# FM33LC0XX register map
File version: 1.0
CPU: Cortex-M0 r1p0, little endian, no MPU, no FPU, 3 interrupt priority bits
Registers are 32-bit, read-write, reset 0x0 unless marked. A register's access mark holds for its fields unless they carry their own. Offsets are from the block's base; [hi:lo] are bit positions.

## RCC — RCC module information
Base 0x40000200
0x00 LKPCR — Lockup reset Control Register
  [1] LKUPRST_EN — LKUPRST_EN field description
0x04 SOFTRST wo — Software Reset Register
  [31:0] SOFTRST — SOFTRST field description
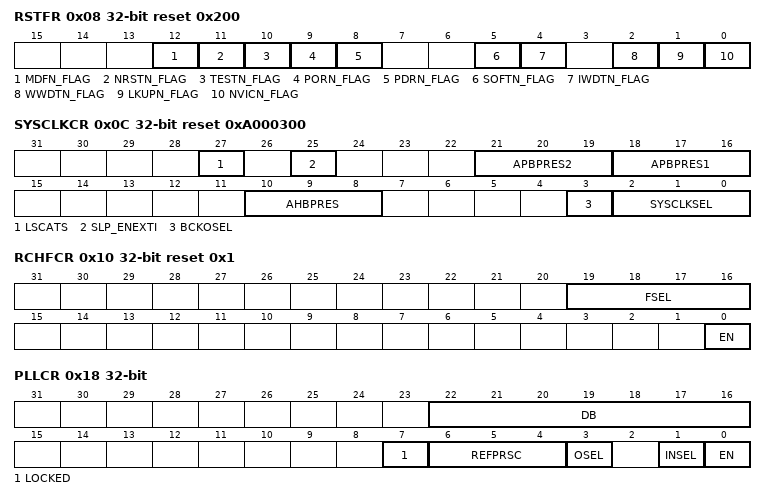
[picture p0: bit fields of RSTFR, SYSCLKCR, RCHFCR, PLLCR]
0x08 RSTFR reset 0x200 — Reset Flag Register
  [12] MDFN_FLAG — MDFN_FLAG field description
  [11] NRSTN_FLAG — NRSTN_FLAG field description
  [10] TESTN_FLAG — TESTN_FLAG field description
  [9] PORN_FLAG — PORN_FLAG field description
  [8] PDRN_FLAG — PDRN_FLAG field description
  [5] SOFTN_FLAG — SOFTN_FLAG field description
  [4] IWDTN_FLAG — IWDTN_FLAG field description
  [2] WWDTN_FLAG — WWDTN_FLAG field description
  [1] LKUPN_FLAG — LKUPN_FLAG field description
  [0] NVICN_FLAG — NVICN_FLAG field description
0x0C SYSCLKCR reset 0xA000300 — System Clock Control Register
  [27] LSCATS — LSCATS field description
  [25] SLP_ENEXTI — SLP_ENEXTI field description
  [21:19] APBPRES2 — APBPRES2 field description
  [18:16] APBPRES1 — APBPRES1 field description
  [10:8] AHBPRES — AHBPRES field description
  [3] BCKOSEL — BCKOSEL field description
  [2:0] SYSCLKSEL — SYSCLKSEL field description
0x10 RCHFCR reset 0x1 — RCHF Control Register
  [19:16] FSEL — FSEL field description
  [0] EN — EN field description
0x14 RCHFTR — RCHF Trim Register
  [6:0] TRIM — TRIM field description
0x18 PLLCR access per field — PLL Control Register
  [22:16] DB rw — DB field description
  [7] LOCKED ro — LOCKED field description
  [6:4] REFPRSC rw — REFPRSC field description
  [3] OSEL rw — OSEL field description
  [1] INSEL rw — INSEL field description
  [0] EN rw — EN field description
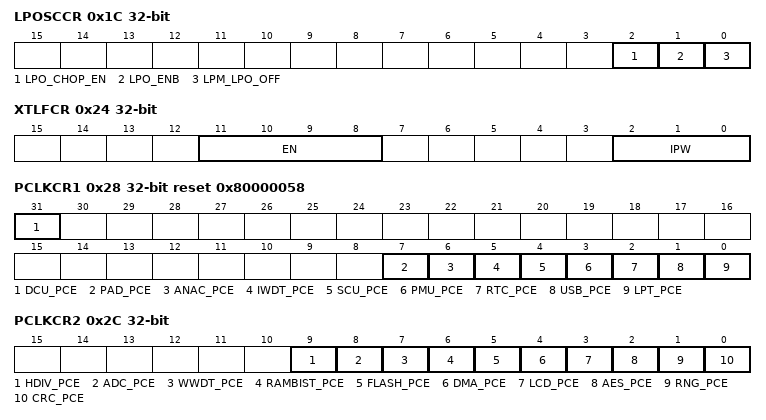
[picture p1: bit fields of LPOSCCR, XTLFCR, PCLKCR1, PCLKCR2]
0x1C LPOSCCR access per field — LPOSC Control Register
  [2] LPO_CHOP_EN rw — LPO_CHOP_EN field description
  [1] LPO_ENB ro — LPO_ENB field description
  [0] LPM_LPO_OFF rw — LPM_LPO_OFF field description
0x20 LPOSCTR — LPOSC Trim Register
  [7:0] LPOTRIM — LPOTRIM field description
0x24 XTLFCR — XTLF Control Register
  [11:8] EN — EN field description
  [2:0] IPW — IPW field description
0x28 PCLKCR1 reset 0x80000058 — Peripheral bus Clock Control Register1
  [31] DCU_PCE — DCU_PCE field description
  [7] PAD_PCE — PAD_PCE field description
  [6] ANAC_PCE — ANAC_PCE field description
  [5] IWDT_PCE — IWDT_PCE field description
  [4] SCU_PCE — SCU_PCE field description
  [3] PMU_PCE — PMU_PCE field description
  [2] RTC_PCE — RTC_PCE field description
  [1] USB_PCE — USB_PCE field description
  [0] LPT_PCE — LPT_PCE field description
0x2C PCLKCR2 — Peripheral bus Clock Control Register2
  [9] HDIV_PCE — HDIV_PCE field description
  [8] ADC_PCE — ADC_PCE field description
  [7] WWDT_PCE — WWDT_PCE field description
  [6] RAMBIST_PCE — RAMBIST_PCE field description
  [5] FLASH_PCE — FLASH_PCE field description
  [4] DMA_PCE — DMA_PCE field description
  [3] LCD_PCE — LCD_PCE field description
  [2] AES_PCE — AES_PCE field description
  [1] RNG_PCE — RNG_PCE field description
  [0] CRC_PCE — CRC_PCE field description
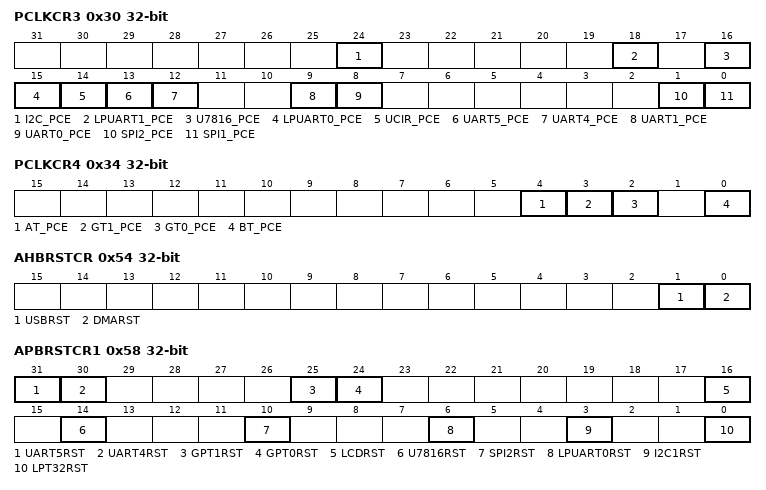
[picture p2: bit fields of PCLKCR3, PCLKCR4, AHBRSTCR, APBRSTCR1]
0x30 PCLKCR3 — Peripheral bus Clock Control Register3
  [24] I2C_PCE — I2C_PCE field description
  [18] LPUART1_PCE — LPUART1_PCE field description
  [16] U7816_PCE — U7816_PCE field description
  [15] LPUART0_PCE — LPUART0_PCE field description
  [14] UCIR_PCE — UCIR_PCE field description
  [13] UART5_PCE — UART5_PCE field description
  [12] UART4_PCE — UART4_PCE field description
  [9] UART1_PCE — UART1_PCE field description
  [8] UART0_PCE — UART0_PCE field description
  [1] SPI2_PCE — SPI2_PCE field description
  [0] SPI1_PCE — SPI1_PCE field description
0x34 PCLKCR4 — Peripheral bus Clock Control Register4
  [4] AT_PCE — AT_PCE field description
  [3] GT1_PCE — GT1_PCE field description
  [2] GT0_PCE — GT0_PCE field description
  [0] BT_PCE — BT_PCE field description
0x38 LSCLKSEL — LSCLK Select Register
  [7:0] SEL — SEL field description
0x44 AHBMCR — AHB Master Control Register
  [0] MPRIL — MPRIL field description
0x50 PRSTEN wo — Peripheral Reset Enable Register
  [31:0] PERHRSTEN — PERHRSTEN field description
0x54 AHBRSTCR — AHB Peripherals Reset Control Register
  [1] USBRST — USBRST field description
  [0] DMARST — DMARST field description
0x58 APBRSTCR1 — APB Peripherals Reset Control Register1
  [31] UART5RST — UART5RST field description
  [30] UART4RST — UART4RST field description
  [25] GPT1RST — GPT1RST field description
  [24] GPT0RST — GPT0RST field description
  [16] LCDRST — LCDRST field description
  [14] U7816RST — U7816RST field description
  [10] SPI2RST — SPI2RST field description
  [6] LPUART0RST — LPUART0RST field description
  [3] I2C1RST — I2C1RST field description
  [0] LPT32RST — LPT32RST field description
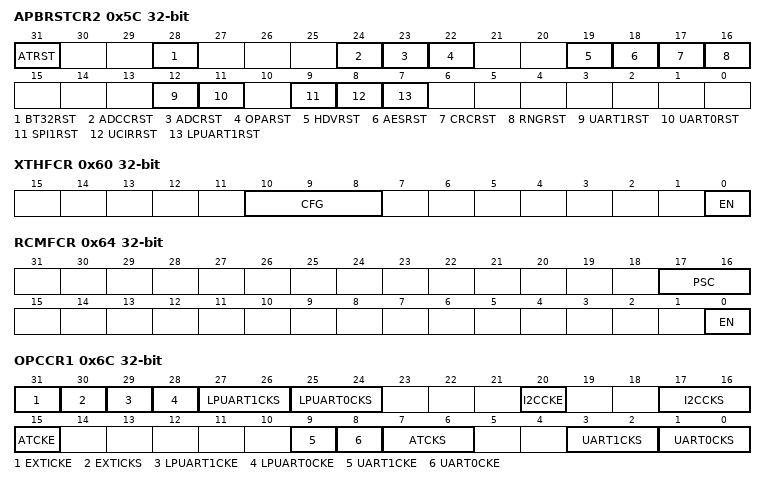
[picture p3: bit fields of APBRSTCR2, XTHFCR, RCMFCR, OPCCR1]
0x5C APBRSTCR2 — APB Peripherals Reset Control Register2
  [31] ATRST — ATRST field description
  [28] BT32RST — BT32RST field description
  [24] ADCCRST — ADCCRST field description
  [23] ADCRST — ADCRST field description
  [22] OPARST — OPARST field description
  [19] HDVRST — HDVRST field description
  [18] AESRST — AESRST field description
  [17] CRCRST — CRCRST field description
  [16] RNGRST — RNGRST field description
  [12] UART1RST — UART1RST field description
  [11] UART0RST — UART0RST field description
  [9] SPI1RST — SPI1RST field description
  [8] UCIRRST — UCIRRST field description
  [7] LPUART1RST — LPUART1RST field description
0x60 XTHFCR — XTHF Control Register
  [10:8] CFG — CFG field description
  [0] EN — EN field description
0x64 RCMFCR — RCMF Control Register
  [17:16] PSC — PSC field description
  [0] EN — EN field description
0x68 RCMFTR — RCMF Trim Register
  [6:0] TRIM — TRIM field description
0x6C OPCCR1 — Peripheral Operation Clock Control Register1
  [31] EXTICKE — EXTICKE field description
  [30] EXTICKS — EXTICKS field description
  [29] LPUART1CKE — LPUART1CKE field description
  [28] LPUART0CKE — LPUART0CKE field description
  [27:26] LPUART1CKS — LPUART1CKS field description
  [25:24] LPUART0CKS — LPUART0CKS field description
  [20] I2CCKE — I2CCKE field description
  [17:16] I2CCKS — I2CCKS field description
  [15] ATCKE — ATCKE field description
  [9] UART1CKE — UART1CKE field description
  [8] UART0CKE — UART0CKE field description
  [7:6] ATCKS — ATCKS field description
  [3:2] UART1CKS — UART1CKS field description
  [1:0] UART0CKS — UART0CKS field description
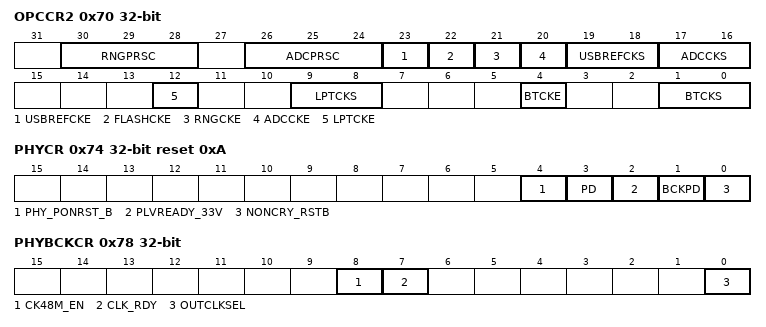
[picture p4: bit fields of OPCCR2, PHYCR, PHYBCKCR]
0x70 OPCCR2 — Peripheral Operation Clock Control Register2
  [30:28] RNGPRSC — RNGPRSC field description
  [26:24] ADCPRSC — ADCPRSC field description
  [23] USBREFCKE — USBREFCKE field description
  [22] FLASHCKE — FLASHCKE field description
  [21] RNGCKE — RNGCKE field description
  [20] ADCCKE — ADCCKE field description
  [19:18] USBREFCKS — USBREFCKS field description
  [17:16] ADCCKS — ADCCKS field description
  [12] LPTCKE — LPTCKE field description
  [9:8] LPTCKS — LPTCKS field description
  [4] BTCKE — BTCKE field description
  [1:0] BTCKS — BTCKS field description
0x74 PHYCR reset 0xA — PHY Control Register
  [4] PHY_PONRST_B — PHY_PONRST_B field description
  [3] PD — PD field description
  [2] PLVREADY_33V — PLVREADY_33V field description
  [1] BCKPD — BCKPD field description
  [0] NONCRY_RSTB — NONCRY_RSTB field description
0x78 PHYBCKCR access per field — PHY BCK Control Register
  [8] CK48M_EN rw — CK48M_EN field description
  [7] CLK_RDY ro — CLK_RDY field description
  [0] OUTCLKSEL rw — OUTCLKSEL field description
